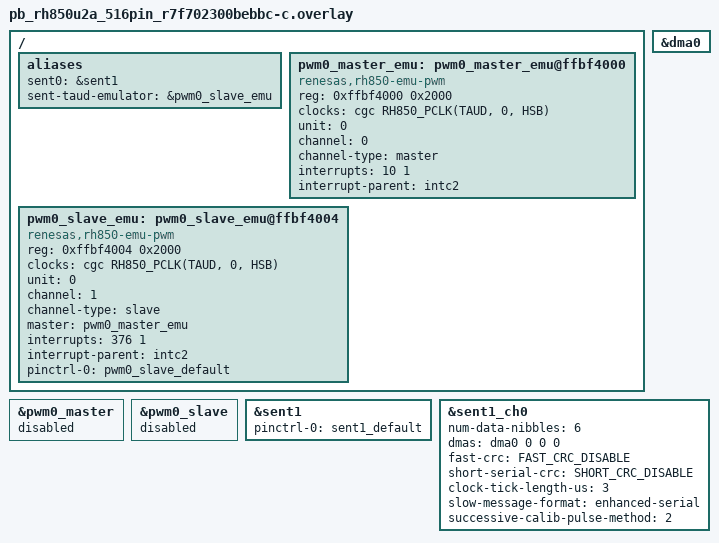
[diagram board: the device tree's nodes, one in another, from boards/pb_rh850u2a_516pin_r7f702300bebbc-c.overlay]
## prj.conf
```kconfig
CONFIG_ZTEST=y

CONFIG_SENT=y
CONFIG_SENT_RENESAS_RH850=y
CONFIG_PWM_RENESAS_RH850=n
CONFIG_PINCTRL=y

CONFIG_LOG=y
CONFIG_LOG_DEFAULT_LEVEL=3
CONFIG_SENT_LOG_LEVEL_DBG=y

CONFIG_MAIN_STACK_SIZE=4096
CONFIG_TEST_EXTRA_STACK_SIZE=2048

CONFIG_SENT_TAUD_TICK_US=3
CONFIG_SENT_TAUD_TX_TIMEOUT_MS=100

CONFIG_SENT_RENESAS_RH850_SERIAL_ENHANCED_FRAME=19

CONFIG_DMA=y
```

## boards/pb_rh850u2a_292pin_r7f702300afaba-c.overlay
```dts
/*
 * Copyright (c) 2026 Renesas Electronics Corporation
 * SPDX-License-Identifier: Apache-2.0
 */

#include <zephyr/dt-bindings/sent/sent.h>

/ {
	aliases {
		sent0 = &sent1;
		sent-taud-emulator = &pwm0_ch1;
	};
};

&pwm0_ch0 {
	pinctrl-0 = <&pwm_default>;
	pinctrl-names = "default";
	status = "okay";
};

&pwm0_ch1 {
	channel-mode = "synchronized";
	interrupt-parent = <&intc2>;
	interrupts = <376 1>;
	status = "okay";
};

&dma0 {
	status = "okay";
};

&sent1 {
	pinctrl-0 = <&sent1_default>;
	pinctrl-names = "default";
	status = "okay";
};

&sent1_ch0 {
	num-data-nibbles = <6>;

	dmas = <&dma0 0 0 0>;
	dma-names = "rx";

	fast-crc = <FAST_CRC_DISABLE>;
	short-serial-crc = <SHORT_CRC_DISABLE>;
	clock-tick-length-us = <3>;
	slow-message-format = "enhanced-serial";
	successive-calib-pulse-method = <2>;
	status = "okay";
};
```

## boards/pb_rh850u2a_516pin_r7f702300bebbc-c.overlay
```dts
/*
 * Copyright (c) 2026 Renesas Electronics Corporation
 * SPDX-License-Identifier: Apache-2.0
 */

#include <zephyr/dt-bindings/sent/sent.h>

/ {
	aliases {
		sent0 = &sent1;
		sent-taud-emulator = &pwm0_slave_emu;
	};

	pwm0_master_emu: pwm0_master_emu@ffbf4000 {
		compatible = "renesas,rh850-emu-pwm";
		reg = <0xffbf4000 0x2000>;
		clocks = <&cgc RH850_PCLK(TAUD, 0, HSB)>;
		unit = <0>;
		channel = <0>;
		channel-type = "master";
		interrupts = <10 1>;
		interrupt-parent = <&intc2>;
		status = "okay";
	};

	pwm0_slave_emu: pwm0_slave_emu@ffbf4004 {
		compatible = "renesas,rh850-emu-pwm";
		reg = <0xffbf4004 0x2000>;
		clocks = <&cgc RH850_PCLK(TAUD, 0, HSB)>;
		unit = <0>;
		channel = <1>;
		channel-type = "slave";
		master = <&pwm0_master_emu>;
		interrupts = <376 1>;
		interrupt-parent = <&intc2>;
		#pwm-cells = <3>;
		status = "okay";

		pinctrl-0 = <&pwm0_slave_default>;
		pinctrl-names = "default";
	};
};

&pwm0_master {
	status = "disabled";
};

&pwm0_slave {
	status = "disabled";
};

&dma0 {
	status = "okay";
};

&sent1 {
	pinctrl-0 = <&sent1_default>;
	pinctrl-names = "default";
	status = "okay";
};

&sent1_ch0 {
	num-data-nibbles = <6>;

	dmas = <&dma0 0 0 0>;
	dma-names = "rx";

	fast-crc = <FAST_CRC_DISABLE>;
	short-serial-crc = <SHORT_CRC_DISABLE>;
	clock-tick-length-us = <3>;
	slow-message-format = "enhanced-serial";
	successive-calib-pulse-method = <2>;
	status = "okay";
};
```

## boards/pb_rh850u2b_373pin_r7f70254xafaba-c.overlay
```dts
/*
 * Copyright (c) 2026 Renesas Electronics Corporation
 * SPDX-License-Identifier: Apache-2.0
 */

#include <zephyr/dt-bindings/sent/sent.h>

/ {
	aliases {
		sent0 = &sent1;
		sent-taud-emulator = &pwm0_ch1;
	};
};

&pwm0_ch0 {
	pinctrl-0 = <&pwm_default>;
	pinctrl-names = "default";
	status = "okay";
};

&pwm0_ch1 {
	channel-mode = "synchronized";
	interrupt-parent = <&intc2>;
	interrupts = <320 1>;
	status = "okay";
};

&dma0 {
	status = "okay";
};

&sent1 {
	pinctrl-0 = <&sent1_default>;
	pinctrl-names = "default";
	status = "okay";
};

&sent1_ch0 {
	num-data-nibbles = <6>;

	dmas = <&dma0 0 0 0>;
	dma-names = "rx";

	fast-crc = <FAST_CRC_DISABLE>;
	short-serial-crc = <SHORT_CRC_DISABLE>;
	clock-tick-length-us = <3>;
	slow-message-format = "enhanced-serial";
	successive-calib-pulse-method = <2>;

	status = "okay";
};
```

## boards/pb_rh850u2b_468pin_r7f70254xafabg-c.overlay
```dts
/*
 * Copyright (c) 2026 Renesas Electronics Corporation
 * SPDX-License-Identifier: Apache-2.0
 */

#include <zephyr/dt-bindings/sent/sent.h>

/ {
	aliases {
		sent0 = &sent1;
		sent-taud-emulator = &pwm0_slave_emu;
	};

	pwm0_master_emu: pwm0_master@ffbf4000 {
		compatible = "renesas,rh850-emu-pwm";
		reg = <0xffbf4000 0x2000>;
		clocks = <&cgc RH850_PCLK(TAUD, 0, HSB)>;
		unit = <0>;
		channel = <0>;
		channel-type = "master";
		interrupts = <10 1>;
		interrupt-parent = <&intc2>;
		status = "okay";
	};

	pwm0_slave_emu: pwm0_slave_emu@ffbf4004 {
		compatible = "renesas,rh850-emu-pwm";
		reg = <0xffbf4004 0x2000>;
		clocks = <&cgc RH850_PCLK(TAUD, 1, HSB)>;
		unit = <0>;
		channel = <1>;
		channel-type = "slave";
		master = <&pwm0_master_emu>;
		interrupts = <320 1>;
		interrupt-parent = <&intc2>;
		#pwm-cells = <3>;
		status = "okay";

		pinctrl-0 = <&pwm0_slave_default>;
		pinctrl-names = "default";
	};
};

&pwm0_master {
	status = "disabled";
};

&pwm0_slave {
	status = "disabled";
};

&dma0 {
	status = "okay";
};

&sent1 {
	pinctrl-0 = <&sent1_default>;
	pinctrl-names = "default";
	status = "okay";
};

&sent1_ch0 {
	num-data-nibbles = <6>;

	dmas = <&dma0 0 0 0>;
	dma-names = "rx";

	fast-crc = <FAST_CRC_DISABLE>;
	short-serial-crc = <SHORT_CRC_DISABLE>;
	clock-tick-length-us = <3>;
	slow-message-format = "enhanced-serial";
	successive-calib-pulse-method = <2>;

	status = "okay";
};
```

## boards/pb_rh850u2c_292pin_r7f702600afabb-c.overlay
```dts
/*
 * Copyright (c) 2026 Renesas Electronics Corporation
 * SPDX-License-Identifier: Apache-2.0
 */

#include <zephyr/dt-bindings/sent/sent.h>

/ {
	aliases {
		sent0 = &sent1;
		sent-taud-emulator = &pwm0_ch1;
	};
};

&pwm0_ch0 {
	pinctrl-0 = <&pwm_default>;
	pinctrl-names = "default";
	status = "okay";
};

&pwm0_ch1 {
	channel-mode = "synchronized";
	interrupt-parent = <&intc2>;
	interrupts = <149 1>;
	status = "okay";
};

&dma0 {
	status = "okay";
};

&sent1 {
	pinctrl-0 = <&sent1_default>;
	pinctrl-names = "default";
	status = "okay";
};

&sent1_ch0 {
	num-data-nibbles = <6>;

	dmas = <&dma0 0 0 0>;
	dma-names = "rx";

	fast-crc = <FAST_CRC_DISABLE>;
	short-serial-crc = <SHORT_CRC_DISABLE>;
	clock-tick-length-us = <3>;
	slow-message-format = "enhanced-serial";
	successive-calib-pulse-method = <2>;
	status = "okay";
};
```

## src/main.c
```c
/*
 * Copyright (c) 2026 Renesas Electronics Corporation
 *
 * SPDX-License-Identifier: Apache-2.0
 */

#include <errno.h>
#include <stdint.h>
#include <string.h>

#include <zephyr/device.h>
#include <zephyr/drivers/sent/sent.h>
#include <zephyr/kernel.h>
#include <zephyr/sys/util.h>
#include <zephyr/ztest.h>

#include "sent_taud_emulator.h"

#define SENT_NODE DT_ALIAS(sent0)
#define SENT_CHANNEL 0U

#define SENT_FAST_FRAME_COUNT 19U
#define SENT_SERIAL_MESSAGE_COUNT 1U
#define SENT_FAST_FRAME_PERIOD_COUNT 9U
#define SENT_STREAM_TERMINATION_PERIOD_COUNT 2U

#define SENT_EXPECTED_SERIAL_ID 0xBCU
#define SENT_EXPECTED_SERIAL_DATA 0xDEFU

#define SENT_RX_TIMEOUT K_MSEC(100U)

#if !DT_NODE_EXISTS(SENT_NODE)
#error "sent0 Devicetree alias is not defined"
#endif

#if !DT_DMAS_HAS_NAME(DT_CHILD(SENT_NODE, channel_0), rx)
#error "The SENT test instance must define an RX DMA specifier"
#endif

static const struct device *const sent_dev = DEVICE_DT_GET(SENT_NODE);

static struct sent_frame fast_frames[SENT_FAST_FRAME_COUNT];
static struct sent_frame serial_frames[SENT_SERIAL_MESSAGE_COUNT];

K_SEM_DEFINE(fast_rx_done, 0, 1);
K_SEM_DEFINE(serial_rx_done, 0, 1);

static volatile uint32_t fast_callback_count;
static volatile uint32_t fast_frame_total;
static volatile uint32_t serial_callback_count;
static volatile uint32_t serial_message_total;

static const uint32_t fsp_sent_pulses[] = {
	/* Dummy frame. */
	56U, 12U, 12U, 12U, 12U, 12U, 12U, 12U, 17U,

	/* Enhanced Serial frames 1 through 6. */
	56U, 23U, 12U, 12U, 12U, 12U, 12U, 12U, 17U,
	56U, 23U, 12U, 12U, 12U, 12U, 12U, 13U, 17U,
	56U, 23U, 12U, 12U, 12U, 12U, 12U, 14U, 17U,
	56U, 23U, 12U, 12U, 12U, 12U, 12U, 15U, 17U,
	56U, 23U, 12U, 12U, 12U, 12U, 12U, 16U, 17U,
	56U, 23U, 12U, 12U, 12U, 12U, 12U, 17U, 17U,

	/* Enhanced Serial frames 7 through 10. */
	56U, 19U, 12U, 12U, 12U, 12U, 12U, 18U, 17U,
	56U, 19U, 12U, 12U, 12U, 12U, 12U, 19U, 17U,
	56U, 23U, 12U, 12U, 12U, 12U, 12U, 20U, 17U,
	56U, 19U, 12U, 12U, 12U, 12U, 12U, 21U, 17U,

	/* Enhanced Serial frames 11 through 12. */
	56U, 27U, 12U, 12U, 12U, 12U, 12U, 22U, 17U,
	56U, 27U, 12U, 12U, 12U, 12U, 12U, 23U, 17U,

	/* Enhanced Serial frames 13 through 16. */
	56U, 19U, 12U, 12U, 12U, 12U, 12U, 24U, 17U,
	56U, 23U, 12U, 12U, 12U, 12U, 12U, 25U, 17U,
	56U, 27U, 12U, 12U, 12U, 12U, 12U, 26U, 17U,
	56U, 19U, 12U, 12U, 12U, 12U, 12U, 27U, 17U,

	/* Enhanced Serial frames 17 through 18. */
	56U, 19U, 12U, 12U, 12U, 12U, 13U, 12U, 17U,
	56U, 19U, 12U, 12U, 12U, 12U, 13U, 13U, 17U,

	/* Stream termination periods. */
	56U,
	56U,
};

BUILD_ASSERT(
	ARRAY_SIZE(fsp_sent_pulses) ==
		((SENT_FAST_FRAME_COUNT * SENT_FAST_FRAME_PERIOD_COUNT) +
		 SENT_STREAM_TERMINATION_PERIOD_COUNT),
	"Unexpected FSP pulse-vector size");

static void rx_fast_frame_cb(const struct device *dev, uint8_t channel_id,
				 uint32_t num_frame, void *user_data)
{
	ARG_UNUSED(dev);
	ARG_UNUSED(user_data);

	if ((channel_id != SENT_CHANNEL) || (num_frame == 0U)) {
		return;
	}

	fast_callback_count++;
	fast_frame_total += num_frame;
	k_sem_give(&fast_rx_done);
}

static void rx_serial_frame_cb(const struct device *dev, uint8_t channel_id,
				   uint32_t num_frame, void *user_data)
{
	ARG_UNUSED(dev);
	ARG_UNUSED(user_data);

	if ((channel_id != SENT_CHANNEL) || (num_frame == 0U)) {
		return;
	}

	serial_callback_count++;
	serial_message_total += num_frame;
	k_sem_give(&serial_rx_done);
}

static struct sent_rx_callback_config fast_cb_cfg = {
	.callback = rx_fast_frame_cb,
	.frame = fast_frames,
	.max_num_frame = ARRAY_SIZE(fast_frames),
	.user_data = NULL,
};

static struct sent_rx_callback_config serial_cb_cfg = {
	.callback = rx_serial_frame_cb,
	.frame = serial_frames,
	.max_num_frame = ARRAY_SIZE(serial_frames),
	.user_data = NULL,
};

static void sent_test_runtime_reset(void)
{
	memset(fast_frames, 0, sizeof(fast_frames));
	memset(serial_frames, 0, sizeof(serial_frames));

	fast_callback_count = 0U;
	fast_frame_total = 0U;
	serial_callback_count = 0U;
	serial_message_total = 0U;

	k_sem_reset(&fast_rx_done);
	k_sem_reset(&serial_rx_done);
}

static int sent_test_start_and_send(struct sent_rx_callback_configs callbacks)
{
	int ret;

	ret = sent_register_callback(sent_dev, SENT_CHANNEL, callbacks);
	if (ret != 0) {
		return ret;
	}

	ret = sent_start_listening(sent_dev, SENT_CHANNEL);
	if (ret != 0) {
		return ret;
	}

	k_msleep(10U);

	return sent_taud_emulator_send_raw(fsp_sent_pulses,
					   ARRAY_SIZE(fsp_sent_pulses));
}

static void *sent_test_setup(void)
{
	int ret;

	zassert_true(device_is_ready(sent_dev), "SENT device is not ready");

	ret = sent_taud_emulator_open();
	zassert_equal(ret, 0, "Failed to open TAUD SENT emulator: %d", ret);

	return NULL;
}

static void sent_test_before(void *fixture)
{
	ARG_UNUSED(fixture);
	sent_test_runtime_reset();
}

static void sent_test_after(void *fixture)
{
	int ret;

	ARG_UNUSED(fixture);

	ret = sent_stop_listening(sent_dev, SENT_CHANNEL);
	zassert_true((ret == 0) || (ret == -EALREADY),
			 "Failed to stop SENT channel: %d", ret);
}

static void sent_test_teardown(void *fixture)
{
	int ret;

	ARG_UNUSED(fixture);

	ret = sent_taud_emulator_close();
	zassert_equal(ret, 0, "Failed to close TAUD SENT emulator: %d", ret);
}

ZTEST(sent_renesas_rh850_dma, test_receive_fast_channel_dma)
{
	struct sent_rx_callback_configs callbacks = {
		.fast = &fast_cb_cfg,
		.serial = NULL,
	};
	int ret;

	ret = sent_test_start_and_send(callbacks);
	zassert_equal(ret, 0, "Failed to start/send Fast DMA test: %d", ret);

	ret = k_sem_take(&fast_rx_done, SENT_RX_TIMEOUT);
	zassert_equal(ret, 0, "Timed out waiting for Fast DMA callback");

	zassert_equal(fast_callback_count, 1U,
			  "Unexpected Fast callback count: %u", fast_callback_count);
	zassert_equal(fast_frame_total, SENT_FAST_FRAME_COUNT,
			  "Unexpected Fast frame count: %u", fast_frame_total);
	zassert_equal(serial_callback_count, 0U,
			  "Serial callback unexpectedly ran: %u", serial_callback_count);

	zassert_equal(fast_frames[0].fast.data_nibbles[0], 0x0U,
			  "Unexpected dummy-frame data nibble");
	zassert_equal(fast_frames[1].fast.data_nibbles[5], 0x0U,
			  "Unexpected first Enhanced frame data nibble");
	zassert_equal(fast_frames[2].fast.data_nibbles[5], 0x1U,
			  "Unexpected second Enhanced frame data nibble");
	zassert_equal(fast_frames[18].fast.data_nibbles[4], 0x1U,
			  "Unexpected final Enhanced frame data nibble 4");
	zassert_equal(fast_frames[18].fast.data_nibbles[5], 0x1U,
			  "Unexpected final Enhanced frame data nibble 5");
}

ZTEST(sent_renesas_rh850_dma, test_receive_serial_channel_cpu_driven)
{
	struct sent_rx_callback_configs callbacks = {
		.fast = NULL,
		.serial = &serial_cb_cfg,
	};
	int ret;

	/*
	 * Only the serial callback is registered. The RSENT driver must keep the
	 * fast receive path moving internally and read the completed serial
	 * message from SRXD using the CPU-driven path.
	 */
	ret = sent_test_start_and_send(callbacks);
	zassert_equal(ret, 0, "Failed to start/send Serial CPU test: %d", ret);

	ret = k_sem_take(&serial_rx_done, SENT_RX_TIMEOUT);
	zassert_equal(ret, 0, "Timed out waiting for Serial CPU callback");

	zassert_equal(serial_callback_count, 1U,
			  "Unexpected Serial callback count: %u", serial_callback_count);
	zassert_equal(serial_message_total, SENT_SERIAL_MESSAGE_COUNT,
			  "Unexpected Serial message count: %u", serial_message_total);
	zassert_equal(fast_callback_count, 0U,
			  "Fast callback unexpectedly ran: %u", fast_callback_count);

	zassert_equal(serial_frames[0].type,
			  SENT_ENHANCED_SERIAL_FRAME_8_BIT_ID,
			  "Unexpected serial frame type: %u",
			  (uint32_t)serial_frames[0].type);
	zassert_equal(serial_frames[0].serial.id,
			  SENT_EXPECTED_SERIAL_ID,
			  "Unexpected serial message ID: 0x%X",
			  serial_frames[0].serial.id);
	zassert_equal(serial_frames[0].serial.data,
			  SENT_EXPECTED_SERIAL_DATA,
			  "Unexpected serial message data: 0x%X",
			  serial_frames[0].serial.data);
}

ZTEST_SUITE(sent_renesas_rh850_dma, NULL, sent_test_setup,
		sent_test_before, sent_test_after, sent_test_teardown);
```

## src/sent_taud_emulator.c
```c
/*
 * Copyright (c) 2026 Renesas Electronics Corporation
 * SPDX-License-Identifier: Apache-2.0
 */

#include "sent_taud_emulator.h"

#include <errno.h>
#include <stdbool.h>
#include <stddef.h>
#include <stdint.h>

#include <zephyr/devicetree.h>
#include <zephyr/drivers/clock_control.h>
#include <zephyr/drivers/pinctrl.h>
#include <zephyr/irq.h>
#include <zephyr/kernel.h>
#include <zephyr/logging/log.h>
#include <zephyr/sys/util.h>

#include "bsp_api.h"

LOG_MODULE_REGISTER(
	sent_taud_emulator,
	CONFIG_LOG_DEFAULT_LEVEL);

/*
 * Alias points to the synchronized output child of the standard TAUD PWM
 * binding. The emulator owns TAUD0 directly, so the normal PWM driver must
 * not be enabled in this test image.
 */
#define SENT_TAUD_EMULATOR_NODE \
	DT_ALIAS(sent_taud_emulator)

#if !DT_NODE_EXISTS(SENT_TAUD_EMULATOR_NODE)
#error "sent-taud-emulator Devicetree alias is not defined"
#endif

#if !DT_NODE_HAS_STATUS_OKAY(SENT_TAUD_EMULATOR_NODE)
#error "SENT TAUD emulator output channel is not enabled"
#endif

#define EMU_MASTER_NODE DT_PARENT(SENT_TAUD_EMULATOR_NODE)

#if !DT_NODE_HAS_STATUS_OKAY(EMU_MASTER_NODE)
#error "SENT TAUD emulator primary channel is not enabled"
#endif

BUILD_ASSERT(!IS_ENABLED(CONFIG_PWM_RENESAS_RH850),
	"SENT emulator owns TAUD0 directly; disable CONFIG_PWM_RENESAS_RH850");

#define EMU_TAUD_UNIT DT_PROP(EMU_MASTER_NODE, unit)
#define EMU_MASTER_CH DT_PROP(EMU_MASTER_NODE, channel)
#define EMU_SLAVE_CH  DT_REG_ADDR(SENT_TAUD_EMULATOR_NODE)

#define EMU_CLOCK_CTLR DT_CLOCKS_CTLR(EMU_MASTER_NODE)
#define EMU_CLOCK_ID   DT_CLOCKS_CELL(EMU_MASTER_NODE, clk_id)

static const struct device *const emulator_clock_dev =
	DEVICE_DT_GET(EMU_CLOCK_CTLR);

#define EMU_MASTER_IRQ          DT_IRQN(EMU_MASTER_NODE)
#define EMU_SLAVE_IRQ           DT_IRQN(SENT_TAUD_EMULATOR_NODE)
#define EMU_MASTER_IRQ_PRIORITY DT_IRQ(EMU_MASTER_NODE, priority)
#define EMU_SLAVE_IRQ_PRIORITY  DT_IRQ(SENT_TAUD_EMULATOR_NODE, priority)

BUILD_ASSERT(EMU_TAUD_UNIT == 0U,
	"Current SENT emulator supports TAUD0 only");
BUILD_ASSERT(EMU_MASTER_CH == 0U,
	"Current SENT emulator expects TAUD0 channel 0 as primary");
BUILD_ASSERT(EMU_SLAVE_CH == 1U,
	"Current SENT emulator expects TAUD0 channel 1 as output");

#define EMU_CH_MASK (BIT(EMU_MASTER_CH) | BIT(EMU_SLAVE_CH))

/* The new binding routes every child pin through the primary node. */
PINCTRL_DT_DEFINE(EMU_MASTER_NODE);
static const struct pinctrl_dev_config *const emulator_pinctrl =
	PINCTRL_DT_DEV_CONFIG_GET(EMU_MASTER_NODE);

/*
 * The current TAUD configuration produces a 10 MHz counter clock.
 *
 * Therefore:
 *
 *     1 us = 10 TAUD counts
 */
#define EMU_COUNTS_PER_US 10U

/*
 * Fixed low-level pulse width used by the TAUD slave output channel.
 *
 * This matches the original FSP test emulator:
 *
 *     slave CDR = 5 SENT ticks
 */
#define EMU_LOW_TICKS 5U

K_SEM_DEFINE(tx_done, 0, 1);

/*
 * Active raw pulse stream.
 *
 * The caller must keep the source array valid until
 * sent_taud_emulator_send_raw() returns.
 */
static const uint32_t *active_pulses;
static size_t active_pulse_count;
static volatile size_t active_pulse_index;
static bool emulator_opened;

/*
 * Debug information retained after a timeout.
 *
 * These variables can be inspected directly from the debugger.
 */
volatile size_t sent_taud_debug_pulse_index;
volatile size_t sent_taud_debug_pulse_count;
volatile uint32_t sent_taud_debug_current_ticks;

/*
 * Convert a raw SENT tick count into the value expected by TAUDnCDR.
 *
 * TAUD counts from the configured value down to zero, therefore the
 * programmed value is:
 *
 *     number_of_counts - 1
 */
static uint16_t sent_taud_ticks_to_counter(uint32_t ticks)
{
	uint64_t counter_value;

	__ASSERT_NO_MSG(ticks > 0U);

	counter_value =
		(uint64_t)ticks *
		(uint64_t)CONFIG_SENT_TAUD_TICK_US *
		(uint64_t)EMU_COUNTS_PER_US;

	__ASSERT_NO_MSG(
		counter_value <=
		((uint64_t)UINT16_MAX + 1U));

	return (uint16_t)(counter_value - 1U);
}

/*
 * The master interrupt is used internally as the slave-channel trigger.
 *
 * The interrupt status must still be acknowledged, but the next pulse is
 * loaded from the slave interrupt.
 */
static void sent_taud_master_isr(const void *arg)
{
	ARG_UNUSED(arg);

	R_BSP_IrqStatusClear(
		(IRQn_Type)EMU_MASTER_IRQ);
}

/*
 * Load the next raw pulse period.
 *
 * The initial period is loaded by sent_taud_emulator_send_raw(). Each
 * subsequent slave interrupt advances to the next array entry.
 */
static void sent_taud_slave_isr(const void *arg)
{
	ARG_UNUSED(arg);

	R_BSP_IrqStatusClear(
		(IRQn_Type)EMU_SLAVE_IRQ);

	sent_taud_debug_pulse_index =
		active_pulse_index;

	sent_taud_debug_pulse_count =
		active_pulse_count;

	/*
	 * Stop after the final pulse period has completed.
	 *
	 * Unlike the FSP test emulator, no SENT_EMU_END_NIBBLE_MARK is
	 * required. The supplied array length determines the end.
	 */
	if ((active_pulses == NULL) ||
	    (active_pulse_index >= active_pulse_count)) {
		R_TAUD0->TAUDnTT =
			EMU_CH_MASK;

		k_sem_give(&tx_done);

		return;
	}

	sent_taud_debug_current_ticks =
		active_pulses[active_pulse_index];

	R_TAUD0
		->TAUDnCDR[EMU_MASTER_CH]
		.TAUDnCDR =
		sent_taud_ticks_to_counter(
			active_pulses[active_pulse_index]);

	active_pulse_index++;
}

static int sent_taud_emulator_clock_init(void)
{
	int ret;

	if (!device_is_ready(emulator_clock_dev)) {
		LOG_ERR("TAUD clock device is not ready");
		return -ENODEV;
	}

	ret = clock_control_on(
		emulator_clock_dev,
		(clock_control_subsys_t)(uintptr_t)EMU_CLOCK_ID);
	if (ret < 0) {
		LOG_ERR("Failed to enable TAUD clock: %d", ret);
		return ret;
	}

	return 0;
}

int sent_taud_emulator_open(void)
{
	int ret;

	if (emulator_opened) {
		return -EALREADY;
	}

	ret = sent_taud_emulator_clock_init();
	if (ret < 0) {
		return ret;
	}

	ret = pinctrl_apply_state(
		emulator_pinctrl,
		PINCTRL_STATE_DEFAULT);

	if (ret < 0) {
		LOG_ERR(
			"Failed to apply TAUD output pinctrl: %d",
			ret);

		return ret;
	}

	/*
	 * Ensure both channels are stopped before reconfiguration.
	 */
	R_TAUD0->TAUDnTT =
		EMU_CH_MASK;

	/*
	 * Configure the TAUD counter clock.
	 *
	 * Peripheral input clock:
	 *
	 *     40 MHz
	 *
	 * Effective TAUD counter clock:
	 *
	 *     10 MHz
	 */
	R_TAUD0->TAUDnTPS_b.TAUDnPRS3 =
		0U;

	R_TAUD0->TAUDnBRS =
		7U;

	R_TAUD0
		->TAUDnCMOR[EMU_MASTER_CH]
		.TAUDnCMOR_b.TAUDnCKS =
		3U;

	R_TAUD0
		->TAUDnCMOR[EMU_MASTER_CH]
		.TAUDnCMOR_b.TAUDnCCS =
		0U;

	R_TAUD0
		->TAUDnCMOR[EMU_SLAVE_CH]
		.TAUDnCMOR_b.TAUDnCKS =
		3U;

	R_TAUD0
		->TAUDnCMOR[EMU_SLAVE_CH]
		.TAUDnCMOR_b.TAUDnCCS =
		0U;

	/*
	 * Configure the master as an interval timer.
	 *
	 * Software starts the master channel. Each expiration supplies the
	 * trigger used by the slave output channel.
	 */
	R_TAUD0
		->TAUDnCMOR[EMU_MASTER_CH]
		.TAUDnCMOR_b.TAUDnMAS =
		1U;

	R_TAUD0
		->TAUDnCMOR[EMU_MASTER_CH]
		.TAUDnCMOR_b.TAUDnSTS =
		0U;

	R_TAUD0
		->TAUDnCMOR[EMU_MASTER_CH]
		.TAUDnCMOR_b.TAUDnMD =
		1U;

	/*
	 * Configure the slave as the SENT waveform output.
	 *
	 * The master-channel interrupt is used as the slave start trigger.
	 * Start triggers received while operating remain valid.
	 */
	R_TAUD0
		->TAUDnCMOR[EMU_SLAVE_CH]
		.TAUDnCMOR_b.TAUDnMAS =
		0U;

	R_TAUD0
		->TAUDnCMOR[EMU_SLAVE_CH]
		.TAUDnCMOR_b.TAUDnSTS =
		4U;

	R_TAUD0
		->TAUDnCMOR[EMU_SLAVE_CH]
		.TAUDnCMOR_b.TAUDnMD =
		9U;

	BUILD_ASSERT(
		EMU_SLAVE_CH == 1U,
		"Current U2x configuration expects TAUD0 channel 1");

	/*
	 * Enable TAUD0 channel 1 output.
	 *
	 * Configuration matches the reference FSP SENT emulator.
	 */
	R_TAUD0->TAUDnTOM_b.TAUDnTOM01 = 1U;
	R_TAUD0->TAUDnTOC_b.TAUDnTOC01 = 0U;
	R_TAUD0->TAUDnTOL_b.TAUDnTOL01 = 1U;
	R_TAUD0->TAUDnTO_b.TAUDnTO01 = 1U;
	R_TAUD0->TAUDnTOE_b.TAUDnTOE01 = 1U;

	active_pulses = NULL;
	active_pulse_count = 0U;
	active_pulse_index = 0U;

	sent_taud_debug_pulse_index = 0U;
	sent_taud_debug_pulse_count = 0U;
	sent_taud_debug_current_ticks = 0U;

	k_sem_reset(&tx_done);

	IRQ_CONNECT(
		EMU_MASTER_IRQ,
		EMU_MASTER_IRQ_PRIORITY,
		sent_taud_master_isr,
		NULL,
		0);

	IRQ_CONNECT(
		EMU_SLAVE_IRQ,
		EMU_SLAVE_IRQ_PRIORITY,
		sent_taud_slave_isr,
		NULL,
		0);

	R_BSP_IrqStatusClear(
		(IRQn_Type)EMU_MASTER_IRQ);

	R_BSP_IrqStatusClear(
		(IRQn_Type)EMU_SLAVE_IRQ);

	irq_enable(EMU_MASTER_IRQ);
	irq_enable(EMU_SLAVE_IRQ);

	emulator_opened = true;

	LOG_INF(
		"TAUD SENT raw emulator opened: "
		"unit=%u master_ch=%u master_irq=%u, "
		"slave_ch=%u slave_irq=%u",
		EMU_TAUD_UNIT,
		EMU_MASTER_CH,
		EMU_MASTER_IRQ,
		EMU_SLAVE_CH,
		EMU_SLAVE_IRQ);

	return 0;
}

int sent_taud_emulator_send_raw(
	const uint32_t *pulse_ticks,
	size_t count)
{
	int ret;

	if (!emulator_opened) {
		return -EACCES;
	}

	if ((pulse_ticks == NULL) ||
	    (count == 0U)) {
		return -EINVAL;
	}

	/*
	 * Validate the entire array before starting TAUD.
	 *
	 * This prevents an invalid later entry from being discovered only
	 * after transmission has already started.
	 */
	for (size_t i = 0U; i < count; i++) {
		uint64_t counter_value;

		if (pulse_ticks[i] == 0U) {
			return -EINVAL;
		}

		counter_value =
			(uint64_t)pulse_ticks[i] *
			(uint64_t)CONFIG_SENT_TAUD_TICK_US *
			(uint64_t)EMU_COUNTS_PER_US;

		if (counter_value >
		    ((uint64_t)UINT16_MAX + 1U)) {
			return -ERANGE;
		}
	}

	/*
	 * Stop both channels before installing the new pulse stream.
	 */
	R_TAUD0->TAUDnTT =
		EMU_CH_MASK;

	active_pulses = pulse_ticks;
	active_pulse_count = count;

	/*
	 * Pulse zero is loaded here, so the ISR begins with pulse one.
	 */
	active_pulse_index = 1U;

	sent_taud_debug_pulse_index = 0U;
	sent_taud_debug_pulse_count = count;
	sent_taud_debug_current_ticks =
		pulse_ticks[0];

	k_sem_reset(&tx_done);

	/*
	 * Load the first falling-edge-to-falling-edge period.
	 */
	R_TAUD0
		->TAUDnCDR[EMU_MASTER_CH]
		.TAUDnCDR =
		sent_taud_ticks_to_counter(
			pulse_ticks[0]);

	/*
	 * Configure the fixed low-level pulse duration on the output
	 * channel, matching the original FSP emulator.
	 */
	R_TAUD0
		->TAUDnCDR[EMU_SLAVE_CH]
		.TAUDnCDR =
		sent_taud_ticks_to_counter(
			EMU_LOW_TICKS);

	R_BSP_IrqStatusClear(
		(IRQn_Type)EMU_MASTER_IRQ);

	R_BSP_IrqStatusClear(
		(IRQn_Type)EMU_SLAVE_IRQ);

	/*
	 * Simultaneously start master and slave.
	 */
	R_TAUD0->TAUDnTS =
		EMU_CH_MASK;

	ret = k_sem_take(
		&tx_done,
		K_MSEC(
			CONFIG_SENT_TAUD_TX_TIMEOUT_MS));

	if (ret != 0) {
		R_TAUD0->TAUDnTT =
			EMU_CH_MASK;

		/*
		 * Prevent either TAUD ISR from observing cleared transmission
		 * state while recovering from a timeout.
		 */
		irq_disable(EMU_MASTER_IRQ);
		irq_disable(EMU_SLAVE_IRQ);

		R_BSP_IrqStatusClear(
			(IRQn_Type)EMU_MASTER_IRQ);

		R_BSP_IrqStatusClear(
			(IRQn_Type)EMU_SLAVE_IRQ);

		active_pulses = NULL;
		active_pulse_count = 0U;
		active_pulse_index = 0U;

		irq_enable(EMU_MASTER_IRQ);
		irq_enable(EMU_SLAVE_IRQ);

		LOG_ERR(
			"TAUD raw transmission timeout: "
			"pulse_index=%u pulse_count=%u "
			"current_ticks=%u",
			(uint32_t)
				sent_taud_debug_pulse_index,
			(uint32_t)
				sent_taud_debug_pulse_count,
			sent_taud_debug_current_ticks);

		return -ETIMEDOUT;
	}

	active_pulses = NULL;
	active_pulse_count = 0U;
	active_pulse_index = 0U;

	return 0;
}

int sent_taud_emulator_close(void)
{
	if (!emulator_opened) {
		return 0;
	}

	irq_disable(EMU_MASTER_IRQ);
	irq_disable(EMU_SLAVE_IRQ);

	R_TAUD0->TAUDnTT =
		EMU_CH_MASK;

	R_BSP_IrqStatusClear(
		(IRQn_Type)EMU_MASTER_IRQ);

	R_BSP_IrqStatusClear(
		(IRQn_Type)EMU_SLAVE_IRQ);

	R_TAUD0->TAUDnTOE_b.TAUDnTOE01 = 0U;
	R_TAUD0->TAUDnTO_b.TAUDnTO01 = 0U;
	R_TAUD0->TAUDnTOL_b.TAUDnTOL01 = 0U;
	R_TAUD0->TAUDnTOC_b.TAUDnTOC01 = 0U;
	R_TAUD0->TAUDnTOM_b.TAUDnTOM01 = 0U;

	active_pulses = NULL;
	active_pulse_count = 0U;
	active_pulse_index = 0U;

	emulator_opened = false;

	k_sem_reset(&tx_done);

	LOG_INF(
		"TAUD SENT raw emulator closed");

	return 0;
}
```

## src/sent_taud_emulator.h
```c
/*
 * Copyright (c) 2026 Renesas Electronics Corporation
 *
 * SPDX-License-Identifier: Apache-2.0
 */

#ifndef SENT_TAUD_EMULATOR_H_
#define SENT_TAUD_EMULATOR_H_

#include <stddef.h>
#include <stdint.h>

#ifdef __cplusplus
extern "C" {
#endif

/**
 * @brief Initialize the TAUD-based SENT waveform emulator.
 *
 * This function configures the TAUD master and slave channels, applies
 * output pinctrl, connects the TAUD interrupts, and enables the output.
 *
 * @retval 0       Emulator initialized successfully.
 * @retval -EALREADY Emulator is already initialized.
 * @retval other   Error returned by pinctrl configuration.
 */
int sent_taud_emulator_open(void);

/**
 * @brief Transmit a raw array of SENT pulse lengths.
 *
 * Every array element represents one falling-edge-to-falling-edge period
 * expressed in SENT ticks.
 *
 * For example, with CONFIG_SENT_TAUD_TICK_US=3:
 *
 *     pulse_ticks[i] = 56
 *
 * produces:
 *
 *     56 * 3 us = 168 us
 *
 * Unlike the original FSP emulator, this API does not require an explicit
 * end marker. The number of pulse periods is supplied by @p count.
 *
 * @param[in] pulse_ticks Raw SENT pulse-length array.
 * @param[in] count       Number of entries in @p pulse_ticks.
 *
 * @retval 0          Transmission completed successfully.
 * @retval -EACCES    Emulator has not been opened.
 * @retval -EINVAL    Invalid pointer, zero count, or zero pulse length.
 * @retval -ERANGE    A pulse exceeds the TAUD counter range.
 * @retval -ETIMEDOUT Transmission did not finish before the configured
 *                    timeout.
 */
int sent_taud_emulator_send_raw(
	const uint32_t *pulse_ticks,
	size_t count);

/**
 * @brief Stop and close the TAUD-based SENT waveform emulator.
 *
 * @retval 0 Emulator closed successfully.
 */
int sent_taud_emulator_close(void);

#ifdef __cplusplus
}
#endif

#endif /* SENT_TAUD_EMULATOR_H_ */
```
